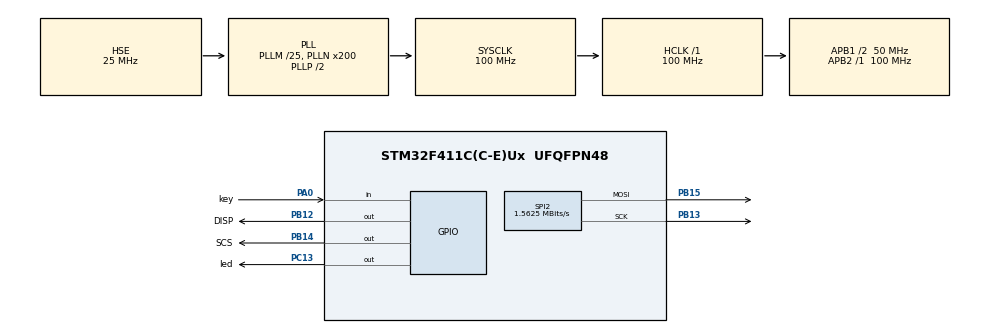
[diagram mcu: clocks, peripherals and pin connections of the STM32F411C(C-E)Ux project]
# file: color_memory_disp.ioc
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Dma.Request0=SPI2_TX
Dma.SPI2_TX.0.Direction=DMA_MEMORY_TO_PERIPH
Dma.SPI2_TX.0.FIFOMode=DMA_FIFOMODE_DISABLE
Dma.SPI2_TX.0.Instance=DMA1_Stream4
Dma.SPI2_TX.0.MemDataAlignment=DMA_MDATAALIGN_BYTE
Dma.SPI2_TX.0.MemInc=DMA_MINC_ENABLE
Dma.SPI2_TX.0.Mode=DMA_NORMAL
Dma.SPI2_TX.0.PeriphDataAlignment=DMA_PDATAALIGN_BYTE
Dma.SPI2_TX.0.PeriphInc=DMA_PINC_DISABLE
Dma.SPI2_TX.0.Priority=DMA_PRIORITY_LOW
Mcu.Family=STM32F4
Mcu.Name=STM32F411C(C-E)Ux
Mcu.Package=UFQFPN48
NVIC.DMA1_Stream4_IRQn=true\:0\:0\:false\:false\:true\:false\:true\:true
NVIC.PriorityGroup=NVIC_PRIORITYGROUP_4
PA0-WKUP.GPIO_Label=key
PA0-WKUP.Signal=GPIO_Input
PA13.Mode=Trace_Asynchronous_SW
PA13.Signal=SYS_JTMS-SWDIO
PA14.Mode=Trace_Asynchronous_SW
PA14.Signal=SYS_JTCK-SWCLK
PB12.GPIO_Label=DISP
PB12.Signal=GPIO_Output
PB13.Mode=TX_Only_Simplex_Unidirect_Master
PB13.Signal=SPI2_SCK
PB14.GPIO_Label=SCS
PB14.Signal=GPIO_Output
PB15.Mode=TX_Only_Simplex_Unidirect_Master
PB15.Signal=SPI2_MOSI
PB3.Mode=Trace_Asynchronous_SW
PB3.Signal=SYS_JTDO-SWO
PC13-ANTI_TAMP.GPIO_Label=led
PC13-ANTI_TAMP.Signal=GPIO_Output
PC14-OSC32_IN.Mode=LSE-External-Oscillator
PC14-OSC32_IN.Signal=RCC_OSC32_IN
PC15-OSC32_OUT.Mode=LSE-External-Oscillator
PC15-OSC32_OUT.Signal=RCC_OSC32_OUT
PH0\ -\ OSC_IN.Mode=HSE-External-Oscillator
PH0\ -\ OSC_IN.Signal=RCC_OSC_IN
PH1\ -\ OSC_OUT.Mode=HSE-External-Oscillator
PH1\ -\ OSC_OUT.Signal=RCC_OSC_OUT
ProjectManager.HeapSize=0x200
ProjectManager.StackSize=0x400
ProjectManager.TargetToolchain=STM32CubeIDE
RCC.48MHZClocksFreq_Value=50000000
RCC.AHBFreq_Value=100000000
RCC.APB1CLKDivider=RCC_HCLK_DIV2
RCC.APB1Freq_Value=50000000
RCC.APB1TimFreq_Value=100000000
RCC.APB2Freq_Value=100000000
RCC.APB2TimFreq_Value=100000000
RCC.CortexFreq_Value=100000000
RCC.HCLKFreq_Value=100000000
RCC.HSE_VALUE=25000000
RCC.HSI_VALUE=16000000
RCC.PLLM=25
RCC.PLLN=200
RCC.PLLSourceVirtual=RCC_PLLSOURCE_HSE
RCC.SYSCLKFreq_VALUE=100000000
RCC.SYSCLKSource=RCC_SYSCLKSOURCE_PLLCLK
RCC.VCOOutputFreq_Value=200000000
SPI2.BaudRatePrescaler=SPI_BAUDRATEPRESCALER_32
SPI2.CalculateBaudRate=1.5625 MBits/s
SPI2.Direction=SPI_DIRECTION_2LINES
SPI2.Mode=SPI_MODE_MASTER
SPI2.VirtualType=VM_MASTER
board=custom

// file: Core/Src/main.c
/* USER CODE BEGIN Header */
/**
  ******************************************************************************
  * @file           : main.c
  * @brief          : Main program body
  ******************************************************************************
  * @attention
  *
  * Copyright (c) 2025 STMicroelectronics.
  * All rights reserved.
  *
  * This software is licensed under terms that can be found in the LICENSE file
  * in the root directory of this software component.
  * If no LICENSE file comes with this software, it is provided AS-IS.
  *
  ******************************************************************************
  */
/* USER CODE END Header */
#include "main.h"

/* USER CODE BEGIN Includes */
#include "tmemdisp.h"
/* USER CODE END Includes */

SPI_HandleTypeDef hspi2;
DMA_HandleTypeDef hdma_spi2_tx;

void SystemClock_Config(void);
static void MX_GPIO_Init(void);
static void MX_DMA_Init(void);
static void MX_SPI2_Init(void);

int main(void)
{

  /* MCU Configuration--------------------------------------------------------*/

  /* Reset of all peripherals, Initializes the Flash interface and the Systick. */
  HAL_Init();

  /* Configure the system clock */
  SystemClock_Config();

  /* Initialize all configured peripherals */
  MX_GPIO_Init();
  MX_DMA_Init();
  MX_SPI2_Init();

  /* Infinite loop */
  /* USER CODE BEGIN WHILE */
  while (1)
  {

	 HAL_GPIO_TogglePin(led_GPIO_Port, led_Pin);
	 HAL_Delay(45);

	 lcd_test();

    /* USER CODE END WHILE */

  }
}

void SystemClock_Config(void)
{
  RCC_OscInitTypeDef RCC_OscInitStruct = {0};
  RCC_ClkInitTypeDef RCC_ClkInitStruct = {0};

  /** Configure the main internal regulator output voltage
  */
  __HAL_RCC_PWR_CLK_ENABLE();
  __HAL_PWR_VOLTAGESCALING_CONFIG(PWR_REGULATOR_VOLTAGE_SCALE1);

  /** Initializes the RCC Oscillators according to the specified parameters
  * in the RCC_OscInitTypeDef structure.
  */
  RCC_OscInitStruct.OscillatorType = RCC_OSCILLATORTYPE_HSE;
  RCC_OscInitStruct.HSEState = RCC_HSE_ON;
  RCC_OscInitStruct.PLL.PLLState = RCC_PLL_ON;
  RCC_OscInitStruct.PLL.PLLSource = RCC_PLLSOURCE_HSE;
  RCC_OscInitStruct.PLL.PLLM = 25;
  RCC_OscInitStruct.PLL.PLLN = 200;
  RCC_OscInitStruct.PLL.PLLP = RCC_PLLP_DIV2;
  RCC_OscInitStruct.PLL.PLLQ = 4;
  if (HAL_RCC_OscConfig(&RCC_OscInitStruct) != HAL_OK)
  {
    Error_Handler();
  }

  /** Initializes the CPU, AHB and APB buses clocks
  */
  RCC_ClkInitStruct.ClockType = RCC_CLOCKTYPE_HCLK|RCC_CLOCKTYPE_SYSCLK
                              |RCC_CLOCKTYPE_PCLK1|RCC_CLOCKTYPE_PCLK2;
  RCC_ClkInitStruct.SYSCLKSource = RCC_SYSCLKSOURCE_PLLCLK;
  RCC_ClkInitStruct.AHBCLKDivider = RCC_SYSCLK_DIV1;
  RCC_ClkInitStruct.APB1CLKDivider = RCC_HCLK_DIV2;
  RCC_ClkInitStruct.APB2CLKDivider = RCC_HCLK_DIV1;

  if (HAL_RCC_ClockConfig(&RCC_ClkInitStruct, FLASH_LATENCY_3) != HAL_OK)
  {
    Error_Handler();
  }
}

static void MX_SPI2_Init(void)
{

  /* SPI2 parameter configuration*/
  hspi2.Instance = SPI2;
  hspi2.Init.Mode = SPI_MODE_MASTER;
  hspi2.Init.Direction = SPI_DIRECTION_2LINES;
  hspi2.Init.DataSize = SPI_DATASIZE_8BIT;
  hspi2.Init.CLKPolarity = SPI_POLARITY_LOW;
  hspi2.Init.CLKPhase = SPI_PHASE_1EDGE;
  hspi2.Init.NSS = SPI_NSS_SOFT;
  hspi2.Init.BaudRatePrescaler = SPI_BAUDRATEPRESCALER_32;
  hspi2.Init.FirstBit = SPI_FIRSTBIT_MSB;
  hspi2.Init.TIMode = SPI_TIMODE_DISABLE;
  hspi2.Init.CRCCalculation = SPI_CRCCALCULATION_DISABLE;
  hspi2.Init.CRCPolynomial = 10;
  if (HAL_SPI_Init(&hspi2) != HAL_OK)
  {
    Error_Handler();
  }

}

static void MX_DMA_Init(void)
{

  /* DMA controller clock enable */
  __HAL_RCC_DMA1_CLK_ENABLE();

  /* DMA interrupt init */
  /* DMA1_Stream4_IRQn interrupt configuration */
  HAL_NVIC_SetPriority(DMA1_Stream4_IRQn, 0, 0);
  HAL_NVIC_EnableIRQ(DMA1_Stream4_IRQn);

}

static void MX_GPIO_Init(void)
{
  GPIO_InitTypeDef GPIO_InitStruct = {0};

  /* GPIO Ports Clock Enable */
  __HAL_RCC_GPIOC_CLK_ENABLE();
  __HAL_RCC_GPIOH_CLK_ENABLE();
  __HAL_RCC_GPIOA_CLK_ENABLE();
  __HAL_RCC_GPIOB_CLK_ENABLE();

  /*Configure GPIO pin Output Level */
  HAL_GPIO_WritePin(led_GPIO_Port, led_Pin, GPIO_PIN_RESET);

  /*Configure GPIO pin Output Level */
  HAL_GPIO_WritePin(GPIOB, DISP_Pin|SCS_Pin, GPIO_PIN_RESET);

  /*Configure GPIO pin : led_Pin */
  GPIO_InitStruct.Pin = led_Pin;
  GPIO_InitStruct.Mode = GPIO_MODE_OUTPUT_PP;
  GPIO_InitStruct.Pull = GPIO_NOPULL;
  GPIO_InitStruct.Speed = GPIO_SPEED_FREQ_LOW;
  HAL_GPIO_Init(led_GPIO_Port, &GPIO_InitStruct);

  /*Configure GPIO pin : key_Pin */
  GPIO_InitStruct.Pin = key_Pin;
  GPIO_InitStruct.Mode = GPIO_MODE_INPUT;
  GPIO_InitStruct.Pull = GPIO_NOPULL;
  HAL_GPIO_Init(key_GPIO_Port, &GPIO_InitStruct);

  /*Configure GPIO pins : DISP_Pin SCS_Pin */
  GPIO_InitStruct.Pin = DISP_Pin|SCS_Pin;
  GPIO_InitStruct.Mode = GPIO_MODE_OUTPUT_PP;
  GPIO_InitStruct.Pull = GPIO_NOPULL;
  GPIO_InitStruct.Speed = GPIO_SPEED_FREQ_LOW;
  HAL_GPIO_Init(GPIOB, &GPIO_InitStruct);

}

void Error_Handler(void)
{
  __disable_irq();
  while (1)
  {
  }
}
